# RT584ZCM33 register map
Series: ARMv8-M Mainline; File version: 1.0
CPU: CM33 r0p0, little endian, MPU, no FPU, VTOR, 3 interrupt priority bits
Registers are 32-bit, read-write, reset 0x0 unless marked. A register's access mark holds for its fields unless they carry their own. Offsets are from the block's base; [hi:lo] are bit positions.

## FLASH_CONTROL_Non-Secure — FLASH_CONTROL Non-Secure Register block
Base 0x40009000
Same registers: FLASH_CONTROL_Secure 0x50009000
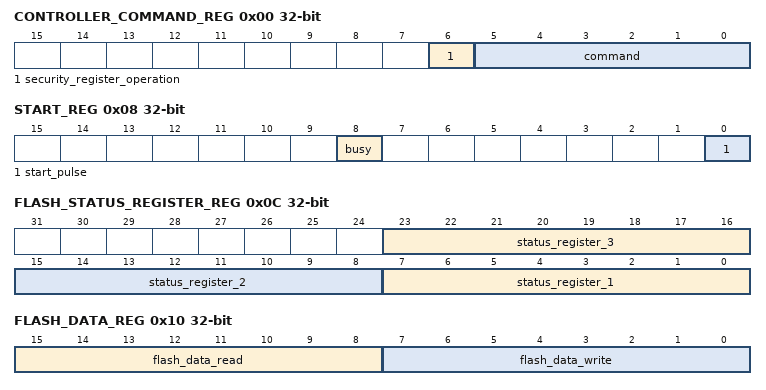
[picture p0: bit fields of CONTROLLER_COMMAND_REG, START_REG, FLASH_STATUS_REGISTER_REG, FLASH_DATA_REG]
0x00 CONTROLLER_COMMAND_REG — controller command
  [6] security_register_operation — security register control 0: memory array 1: security register
    0=B_6_ITEM0 (memory array); 1=B_6_ITEM1 (security register)
  [5:0] command — Command set for flash operation. Please refer to reference for the detail.
    0=B_0_to_5 (Command set for flash operation. Please refer to reference for the detail.)
0x04 ADDR_REG — setting flash address for operation (value can map to 0x80000000)
0x08 START_REG — start
  [8] busy ro — controller status
    0=B_8 (controller status)
  [0] start_pulse wo — control start
    0=B_0 (control start)
0x0C FLASH_STATUS_REGISTER_REG — flash status register
  [23:16] status_register_3 — write status register -3
    0=B_16_to_23 (write status register -3)
  [15:8] status_register_2 — write status register -2
    0=B_8_to_15 (write status register -2)
  [7:0] status_register_1 — write status register -1
    0=B_0_to_7 (write status register -1)
0x10 FLASH_DATA_REG — flash data
  [15:8] flash_data_read ro — read back data from flash: byte read data, byte read SFDP, read status register
    0=B_8_to_15 (read back data from flash: byte read data, byte read SFDP, read status register)
  [7:0] flash_data_write — write data into flash: byte program data
    0=B_0_to_7 (write data into flash: byte program data)
0x14 MEM_ADDR_REG — page program/read data from/to memory address (need 4 byte aligned)
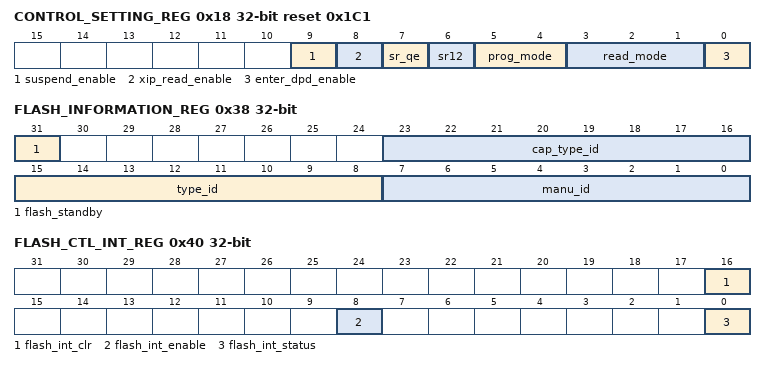
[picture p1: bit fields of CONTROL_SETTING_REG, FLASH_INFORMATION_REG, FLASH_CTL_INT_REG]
0x18 CONTROL_SETTING_REG reset 0x1C1 — control setting
  [9] suspend_enable — when flash program/erase, cache can aceess flash by AHB bus 0: disable 1: enable
    0=B_9_ITEM0 (disable); 1=B_9_ITEM1 (enable)
  [8] xip_read_enable — cache can aceess flash by AHB bus 0: disable 1: enable
    0=B_8_ITEM0 (disable); 1=B_8_ITEM1 (enable)
  [7] sr_qe — QE @ status register 0: status register 1[6] 1: status register 2[1] (or status register[9] )
    0=B_7_ITEM0 (status register 1[6]); 1=B_7_ITEM1 (status register 2[1] (or status register[9] ))
  [6] sr12 — status register 1 & 2 can use instruction 01h write 00: no 1: yes
    0=B_6_ITEM0 (no); 1=B_6_ITEM1 (yes)
  [5:4] prog_mode — 0: 1-1-1 program (instruction = 02h) 1: 1-1-2 program (instruction = A2h, only for PUYA) 2: 1-1-4 program (instruciton = 32h) 3: 1-1-4 program (instruction = 38h)
    0=B_4_to_5_ITEM0 (1-1-1 program (instruction = 02h)); 1=B_4_to_5_ITEM1 (1-1-2 program (instruction = A2h, only for PUYA)); 2=B_4_to_5_ITEM2 (1-1-4 program (instruciton = 32h)); 3=B_4_to_5_ITEM3 (1-1-4 program (instruction = 38h))
  [3:1] read_mode — 0: 1-1-1 read (instruction = 0Bh) 1: 1-1-2 read (instruction = 3Bh) 2: 1-1-4 read (instruction = 6Bh) 4: 1-1-1 read (instruciton = 0Bh) 5: 1-2-2 read (instruciton = BBh, no support contious mode) 6: 1-4-4 read (instruciton = EBh, no support contious mode)
    0=B_1_to_3 (0: 1-1-1 read (instruction = 0Bh) 1: 1-1-2 read (instruction = 3Bh) 2: 1-1-4 read (instruction = 6Bh) 4: 1-1-1 read (instruciton = 0Bh) 5: 1-2-2 read (instruciton = BBh, no support contious mode) 6: 1-4-4 read (instruciton = EBh, no support contious mode))
  [0] enter_dpd_enable — enter deep power down when system @ sleep
    0=B_0 (enter deep power down when system @ sleep)
0x1C CRC_REG ro — crc
  [7:0] page_crc — page program/verify for page crc result
    0=B_0_to_7 (page program/verify for page crc result)
0x20 DPD_REG — dpd
  [13:0] dpd_time — deep power down time
0x24 RDPD_REG — rdpd
  [13:0] rdpd_time — release deep power down time
0x28 SUSPEND_REG — suspend
  [13:0] suspend_time
0x2C RESUME_REG — resume
  [13:0] resume_time
0x34 PAGE_READ_WORD_REG reset 0xFF — page read word
  [7:0] page_read_byte — need 4 byte (double word, [1:0] must = 2'b11)
    0=B_0_to_7 (need 4 byte (double word, [1:0] must = 2'b11))
0x38 FLASH_INFORMATION_REG ro — flash information
  [31] flash_standby — flash ready for access afer exiting dpd mode/startup
    0=B_31 (flash ready for access afer exiting dpd mode/startup)
  [23:16] cap_type_id — flash capacity ID
    0=B_16_to_23 (flash capacity ID)
  [15:8] type_id — flash type ID
    0=B_8_to_15 (flash type ID)
  [7:0] manu_id — flash manu ID
    0=B_0_to_7 (flash manu ID)
0x40 FLASH_CTL_INT_REG — flash ctl int
  [16] flash_int_clr wo — interrpt clear
    0=B_16 (interrpt clear)
  [8] flash_int_enable — interrpt enable
    0=B_8 (interrpt enable)
  [0] flash_int_status ro — interrupt when start finish
    0=B_0 (interrupt when start finish)
0x44 OPERATION_PATTERN_MATCH_REG — need write RABT ASSCII (52_41_42_54) for start operation
